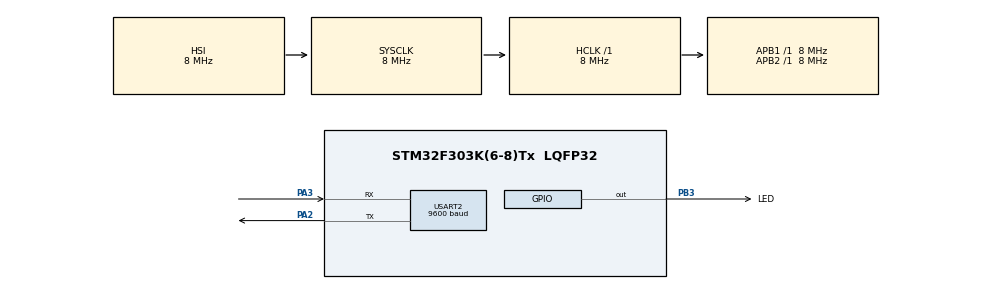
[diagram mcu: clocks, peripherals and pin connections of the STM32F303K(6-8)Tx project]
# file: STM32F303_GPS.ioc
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Mcu.Family=STM32F3
Mcu.Name=STM32F303K(6-8)Tx
Mcu.Package=LQFP32
NVIC.PriorityGroup=NVIC_PRIORITYGROUP_4
NVIC.USART2_IRQn=true\:0\:0\:false\:false\:true\:true\:true
PA13.GPIO_Label=SWDIO
PA13.Mode=Serial_Wire
PA13.Signal=SYS_JTMS-SWDIO
PA14.GPIO_Label=SWCLK
PA14.Mode=Serial_Wire
PA14.Signal=SYS_JTCK-SWCLK
PA2.Mode=Asynchronous
PA2.Signal=USART2_TX
PA3.Mode=Asynchronous
PA3.Signal=USART2_RX
PB3.GPIO_Label=LED
PB3.Signal=GPIO_Output
PF0\ /\ OSC_IN.GPIO_Label=MCO
PF0\ /\ OSC_IN.Mode=HSE-External-Clock-Source
PF0\ /\ OSC_IN.Signal=RCC_OSC_IN
ProjectManager.HeapSize=0x200
ProjectManager.StackSize=0x400
ProjectManager.TargetToolchain=STM32CubeIDE
RCC.AHBFreq_Value=8000000
RCC.APB1Freq_Value=8000000
RCC.APB2Freq_Value=8000000
RCC.CortexFreq_Value=8000000
RCC.HSE_VALUE=8000000
RCC.HSI_VALUE=8000000
RCC.SYSCLKFreq_VALUE=8000000
USART2.BaudRate=9600
USART2.Mode=MODE_RX
USART2.VirtualMode-Asynchronous=VM_ASYNC
board=NUCLEO-F303K8

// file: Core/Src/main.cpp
/* USER CODE BEGIN Header */
/**
  ******************************************************************************
  * @file           : main.c
  * @brief          : Main program body
  ******************************************************************************
  * @attention
  *
  * <h2><center>&copy; Copyright (c) 2020 STMicroelectronics.
  * All rights reserved.</center></h2>
  *
  * This software component is licensed by ST under BSD 3-Clause license,
  * the "License"; You may not use this file except in compliance with the
  * License. You may obtain a copy of the License at:
  *                        opensource.org/licenses/BSD-3-Clause
  *
  ******************************************************************************
  */
/* USER CODE END Header */

#include "main.h"
#include "usart.h"
#include "gpio.h"
#include "GPS/GPS.h"

/* USER CODE BEGIN Includes */
GPS gps;
/* USER CODE END Includes */

void SystemClock_Config(void);

int main(void)
{

  /* MCU Configuration--------------------------------------------------------*/

  /* Reset of all peripherals, Initializes the Flash interface and the Systick. */
  HAL_Init();

  /* Configure the system clock */
  SystemClock_Config();

  /* Initialize all configured peripherals */
  MX_GPIO_Init();
  MX_USART2_UART_Init();
  /* USER CODE BEGIN 2 */
  HAL_UART_MspInit(&huart2);
  gps.init();

  /* USER CODE END 2 */

  /* Infinite loop */
  while (1)
  {

  }
}

void SystemClock_Config(void)
{
  RCC_OscInitTypeDef RCC_OscInitStruct = {0};
  RCC_ClkInitTypeDef RCC_ClkInitStruct = {0};

  /** Initializes the CPU, AHB and APB busses clocks
  */
  RCC_OscInitStruct.OscillatorType = RCC_OSCILLATORTYPE_HSI;
  RCC_OscInitStruct.HSIState = RCC_HSI_ON;
  RCC_OscInitStruct.HSICalibrationValue = RCC_HSICALIBRATION_DEFAULT;
  RCC_OscInitStruct.PLL.PLLState = RCC_PLL_NONE;
  if (HAL_RCC_OscConfig(&RCC_OscInitStruct) != HAL_OK)
  {
    Error_Handler();
  }
  /** Initializes the CPU, AHB and APB busses clocks
  */
  RCC_ClkInitStruct.ClockType = RCC_CLOCKTYPE_HCLK|RCC_CLOCKTYPE_SYSCLK
                              |RCC_CLOCKTYPE_PCLK1|RCC_CLOCKTYPE_PCLK2;
  RCC_ClkInitStruct.SYSCLKSource = RCC_SYSCLKSOURCE_HSI;
  RCC_ClkInitStruct.AHBCLKDivider = RCC_SYSCLK_DIV1;
  RCC_ClkInitStruct.APB1CLKDivider = RCC_HCLK_DIV1;
  RCC_ClkInitStruct.APB2CLKDivider = RCC_HCLK_DIV1;

  if (HAL_RCC_ClockConfig(&RCC_ClkInitStruct, FLASH_LATENCY_0) != HAL_OK)
  {
    Error_Handler();
  }
}

/* USER CODE BEGIN 4 */

/*Interrupt Handler*/
void HAL_UART_RxCpltCallback(UART_HandleTypeDef *UartHandle) {

	gps.gpsInterrupt(UartHandle);
}

/* USER CODE END 4 */

void Error_Handler(void)
{
}

/************************ (C) COPYRIGHT STMicroelectronics *****END OF FILE****/
